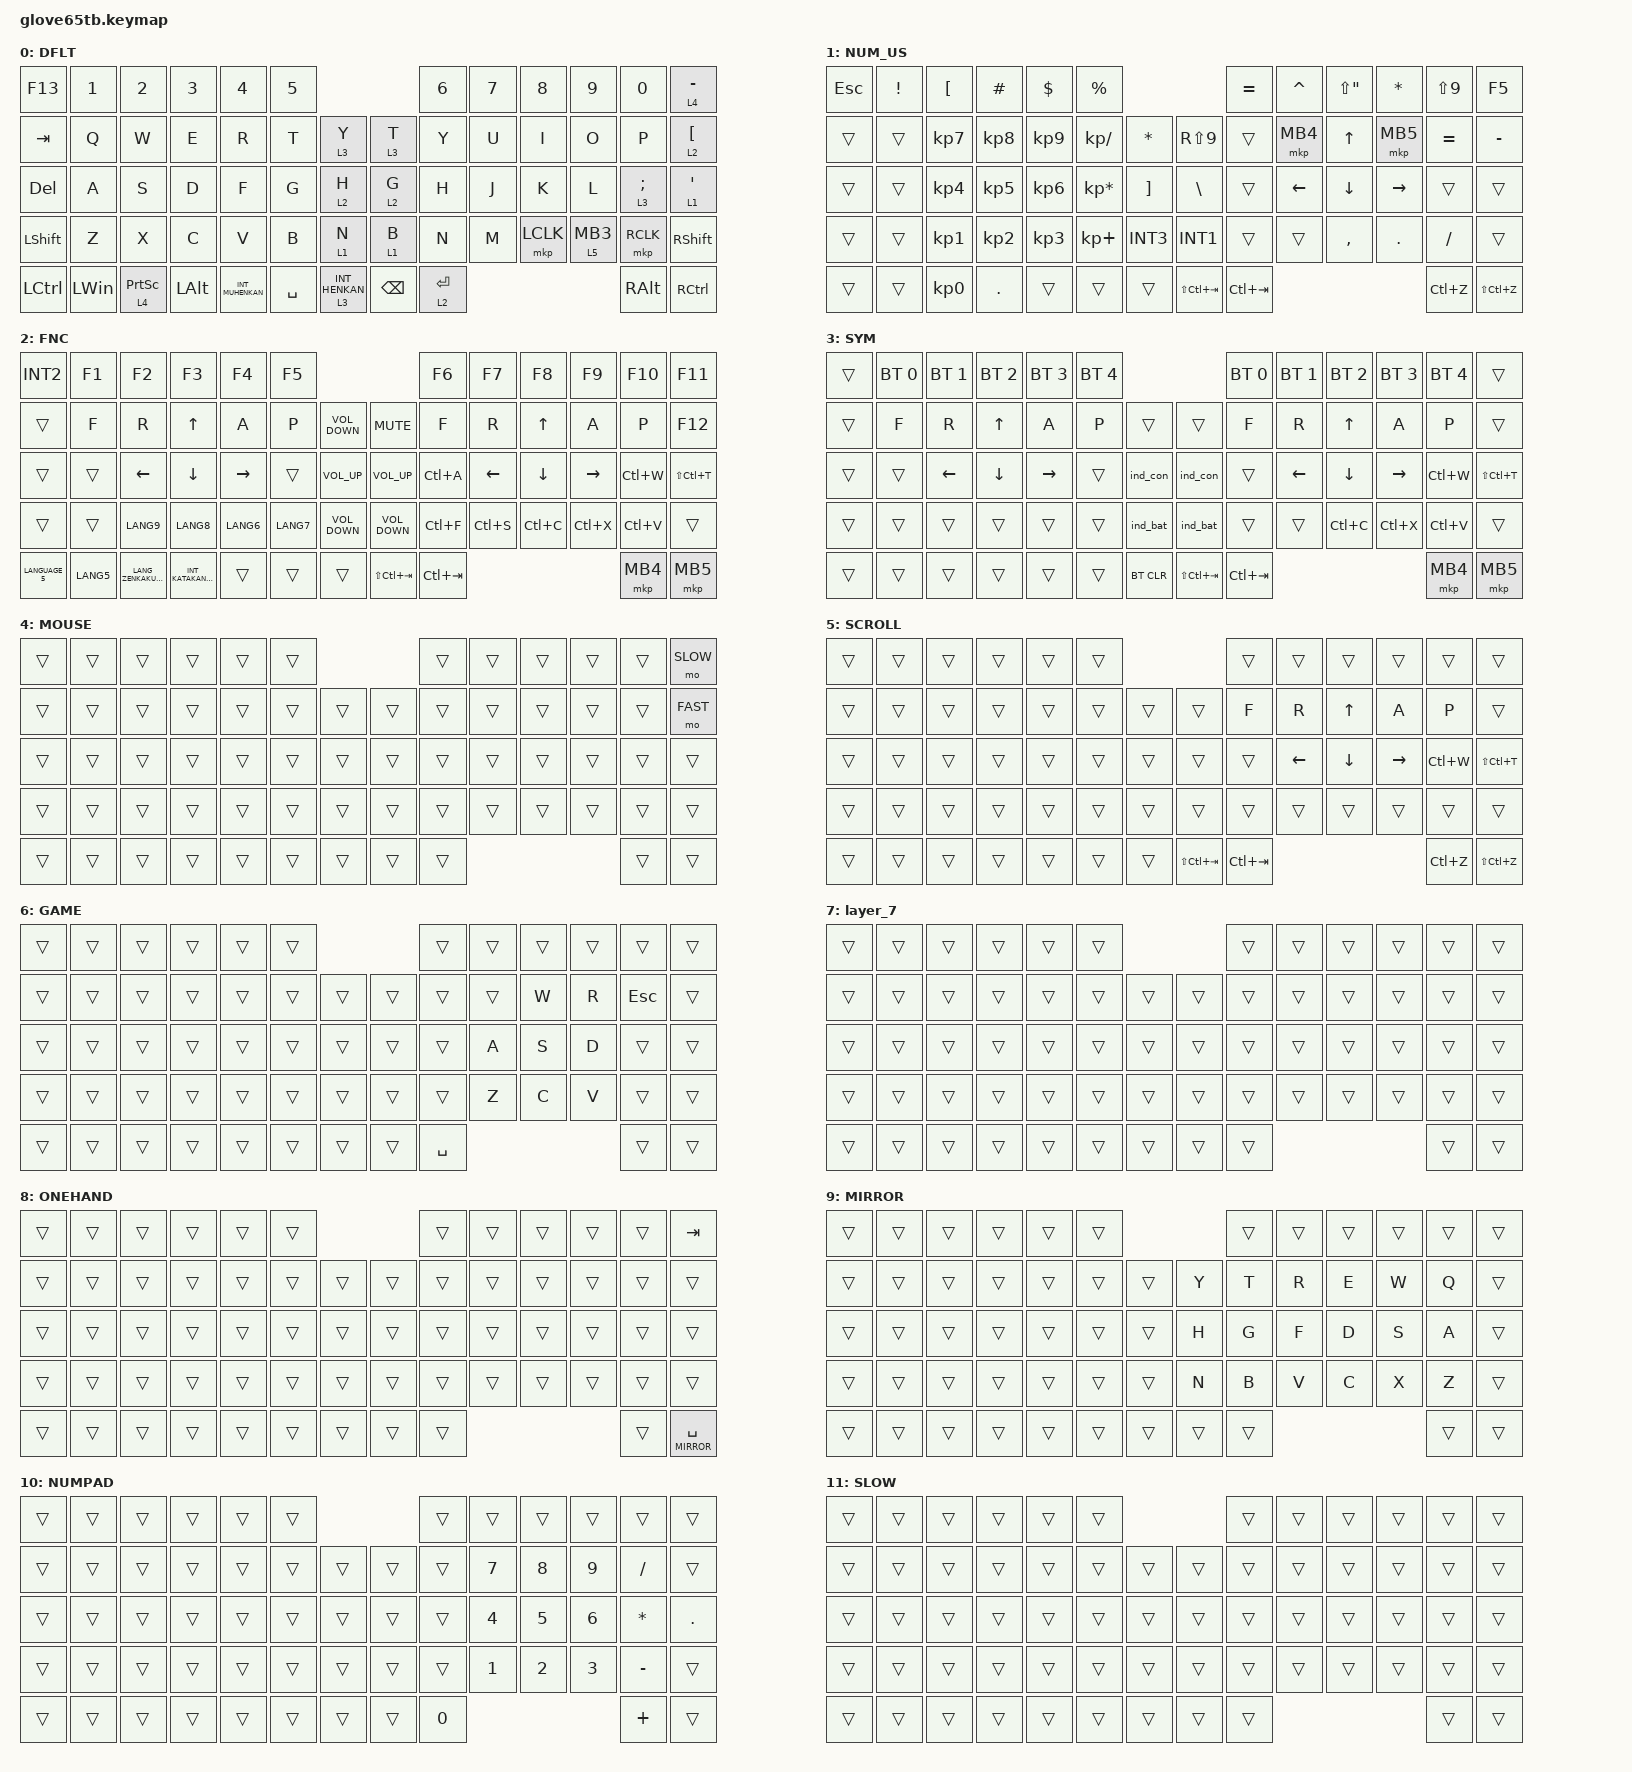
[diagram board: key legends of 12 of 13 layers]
#define ZMK_POINTING_DEFAULT_SCRL_VAL 150

#include <behaviors/rgbled_widget.dtsi>
#include <dt-bindings/zmk/input_transform.h>
#include <input/processors.dtsi>
#include <zephyr/dt-bindings/input/input-event-codes.h>
#include <behaviors.dtsi>
#include <dt-bindings/zmk/bt.h>
#include <dt-bindings/zmk/keys.h>
#include <dt-bindings/zmk/pointing.h>

// Layer Numbering

#define DEFAULT 0
#define NUM     1
#define SYM     2
#define FUN     3
#define MOUSE   4
#define SCROLL  5
#define GAME    6
#define ONEHAND 8
#define MIRROR  9
#define NUMPAD  10
#define SLOW    11
#define FAST    12

&mmv {
    delay-ms = <20>;
    trigger-period-ms = <5>;
    time-to-max-speed-ms = <100>;
    acceleration-exponent = <2>;
};

&msc {
    delay-ms = <3>;
    trigger-period-ms = <3>;
    time-to-max-speed-ms = <100>;
    acceleration-exponent = <0>;
};

/ {
    input_processors {
        zip_wheel_scaler: zip_wheel_scaler {
            compatible = "zmk,input-processor-scaler";
            #input-processor-cells = <2>;
            type = <INPUT_EV_REL>;
            codes = <INPUT_REL_WHEEL>;
            track-remainders;
        };
    };
};

/ {
    combos {
        compatible = "zmk,combos";

        scroll {
            bindings = <&mo 5>;
            key-positions = <50 51>;
        };

        toggle_onehand {
            bindings = <&tog ONEHAND>;
            key-positions = <63 64>;
        };

        toggle_numpad {
            bindings = <&tog NUMPAD>;
            key-positions = <61 62>;
        };

        toggle_game {
            bindings = <&tog GAME>;
            key-positions = <40 53>;
        };

        check_bt_connection {
            bindings = <&ind_con>;
            key-positions = <54 64>;
        };
    };

    behaviors {
        sensor_rotate_kp: sensor_rotate_kp {
            compatible = "zmk,behavior-sensor-rotate-var";
            #sensor-binding-cells = <2>;
            bindings = <&kp>, <&kp>;
        };

        mouse_wheel_scroll: mouse_wheel_scroll {
            compatible = "zmk,behavior-sensor-rotate-var";
            #sensor-binding-cells = <2>;
            bindings = <&msc>, <&msc>;

            tap-ms = <20>;
        };

        lt_mouse_layer: lt_mouse_layer {
            compatible = "zmk,behavior-hold-tap";
            label = "LAYER_TAP_MOUSE";
            bindings = <&mo>, <&mkp>;

            #binding-cells = <2>;
            tapping-term-ms = <200>;
        };
    };

    keymap {
        compatible = "zmk,keymap";

        default_layer {
            label = "DFLT";
            bindings = <
&kp F13         &kp N1        &kp N2             &kp N3        &kp N4              &kp N5                                        &kp N6       &kp N7  &kp N8     &kp N9                 &kp N0           &lt 4 MINUS
&kp TAB         &kp Q         &kp W              &kp E         &kp R               &kp T        &lt 3 Y           &lt 3 T        &kp Y        &kp U   &kp I      &kp O                  &kp P            &lt 2 LBKT
&kp DEL         &kp A         &kp S              &kp D         &kp F               &kp G        &lt 2 H           &lt 2 G        &kp H        &kp J   &kp K      &kp L                  &lt 3 SEMICOLON  &lt 1 APOS
&kp LEFT_SHIFT  &kp Z         &kp X              &kp C         &kp V               &kp B        &lt 1 N           &lt 1 B        &kp N        &kp M   &mkp LCLK  &lt_mouse_layer 5 MB3  &mkp RCLK        &kp RIGHT_SHIFT
&kp LCTRL       &kp LEFT_WIN  &lt 4 PRINTSCREEN  &kp LEFT_ALT  &kp INT_MUHENKAN    &kp SPACE    &lt 3 INT_HENKAN  &kp BACKSPACE  &lt 2 ENTER                                            &kp RIGHT_ALT    &kp RCTRL
            >;

            sensor-bindings = <&mouse_wheel_scroll SCRL_UP SCRL_DOWN>;
        };

        num_us_layer {
            label = "NUM_US";
            bindings = <
&kp ESC  &kp EXCL  &kp LBKT         &kp HASH         &kp DOLLAR       &kp PERCENT                                  &kp EQUAL    &kp CARET       &kp LS(DOUBLE_QUOTES)  &kp ASTRK        &kp LS(N9)  &kp F5
&trans   &trans    &kp KP_NUMBER_7  &kp KP_NUMBER_8  &kp KP_NUMBER_9  &kp KP_DIVIDE    &kp ASTRK  &kp RS(N9)       &trans       &mkp MB4        &kp UP_ARROW           &mkp MB5         &kp EQUAL   &kp MINUS
&trans   &trans    &kp KP_NUMBER_4  &kp KP_NUMBER_5  &kp KP_NUMBER_6  &kp KP_ASTERISK  &kp RBKT   &kp BSLH         &trans       &kp LEFT_ARROW  &kp DOWN_ARROW         &kp RIGHT_ARROW  &trans      &trans
&trans   &trans    &kp KP_NUMBER_1  &kp KP_NUMBER_2  &kp KP_NUMBER_3  &kp KP_PLUS      &kp INT3   &kp INT1         &trans       &trans          &kp COMMA              &kp PERIOD       &kp SLASH   &trans
&trans   &trans    &kp KP_NUMBER_0  &kp PERIOD       &trans           &trans           &trans     &kp LS(LC(TAB))  &kp LC(TAB)                                                          &kp LC(Z)   &kp LS(LC(Z))
            >;
        };

        function_layer {
            label = "FNC";
            bindings = <
&kp INT2        &kp F1     &kp F2                   &kp F3                    &kp F4           &kp F5                                           &kp F6       &kp F7          &kp F8          &kp F9           &kp F10    &kp F11
&trans          &kp F      &kp R                    &kp UP_ARROW              &kp A            &kp P      &kp C_VOLUME_DOWN  &kp K_MUTE         &kp F        &kp R           &kp UP_ARROW    &kp A            &kp P      &kp F12
&trans          &trans     &kp LEFT_ARROW           &kp DOWN_ARROW            &kp RIGHT_ARROW  &trans     &kp C_VOLUME_UP    &kp C_VOLUME_UP    &kp LC(A)    &kp LEFT_ARROW  &kp DOWN_ARROW  &kp RIGHT_ARROW  &kp LC(W)  &kp LS(LC(T))
&trans          &trans     &kp LANG9                &kp LANG8                 &kp LANG6        &kp LANG7  &kp C_VOLUME_DOWN  &kp C_VOLUME_DOWN  &kp LC(F)    &kp LC(S)       &kp LC(C)       &kp LC(X)        &kp LC(V)  &trans
&kp LANGUAGE_5  &kp LANG5  &kp LANG_ZENKAKUHANKAKU  &kp INT_KATAKANAHIRAGANA  &trans           &trans     &trans             &kp LS(LC(TAB))    &kp LC(TAB)                                                   &mkp MB4   &mkp MB5
            >;

            sensor-bindings = <&sensor_rotate_kp C_VOLUME_DOWN C_VOLUME_UP>;
        };

        symbol_layer {
            label = "SYM";
            bindings = <
&trans  &bt BT_SEL 0  &bt BT_SEL 1  &bt BT_SEL 2  &bt BT_SEL 3  &bt BT_SEL 4                             &bt BT_SEL 0 &bt BT_SEL 1    &bt BT_SEL 2    &bt BT_SEL 3     &bt BT_SEL 4 &trans
&trans  &kp F         &kp R         &kp UP        &kp A         &kp P         &trans    &trans           &kp F        &kp R           &kp UP_ARROW    &kp A            &kp P      &trans
&trans  &trans        &kp LEFT      &kp DOWN      &kp RIGHT     &trans        &ind_con  &ind_con         &trans       &kp LEFT_ARROW  &kp DOWN_ARROW  &kp RIGHT_ARROW  &kp LC(W)  &kp LS(LC(T))
&trans  &trans        &trans        &trans        &trans        &trans        &ind_bat  &ind_bat         &trans       &trans          &kp LC(C)       &kp LC(X)        &kp LC(V)  &trans
&trans  &trans        &trans        &trans        &trans        &trans        &bt BT_CLR  &kp LS(LC(TAB))  &kp LC(TAB)                                                   &mkp MB4   &mkp MB5
            >;
        };

        mouse_layer {
            label = "MOUSE";
            bindings = <
&trans  &trans  &trans  &trans  &trans  &trans                                  &trans  &trans  &trans  &trans  &trans  &mo SLOW
&trans  &trans  &trans  &trans  &trans  &trans  &trans  &trans                  &trans  &trans  &trans  &trans  &trans  &mo FAST
&trans  &trans  &trans  &trans  &trans  &trans  &trans  &trans                  &trans  &trans  &trans  &trans  &trans  &trans
&trans  &trans  &trans  &trans  &trans  &trans  &trans  &trans                  &trans  &trans  &trans  &trans  &trans  &trans
&trans  &trans  &trans  &trans  &trans  &trans  &trans  &trans  &trans                                  &trans  &trans
            >;
        };

        scroll_layer {
            label = "SCROLL";
            bindings = <
&trans  &trans  &trans  &trans  &trans  &trans                           &trans       &trans    &trans    &trans     &trans     &trans
&trans  &trans  &trans  &trans  &trans  &trans  &trans  &trans           &kp F        &kp R     &kp UP    &kp A      &kp P      &trans
&trans  &trans  &trans  &trans  &trans  &trans  &trans  &trans           &trans       &kp LEFT  &kp DOWN  &kp RIGHT  &kp LC(W)  &kp LS(LC(T))
&trans  &trans  &trans  &trans  &trans  &trans  &trans  &trans           &trans       &trans    &trans    &trans     &trans     &trans
&trans  &trans  &trans  &trans  &trans  &trans  &trans  &kp LS(LC(TAB))  &kp LC(TAB)                                 &kp LC(Z)  &kp LS(LC(Z))
            >;
        };

        game_layer {
            label = "GAME";
            bindings = <
&trans  &trans  &trans  &trans  &trans  &trans                                  &trans  &trans  &trans  &trans    &trans   &trans
&trans  &trans  &trans  &trans  &trans  &trans  &trans  &trans                  &trans  &trans  &kp W   &kp R     &kp ESC  &trans
&trans  &trans  &trans  &trans  &trans  &trans  &trans  &trans                  &trans  &kp A   &kp S   &kp D     &trans   &trans
&trans  &trans  &trans  &trans  &trans  &trans  &trans  &trans                  &trans  &kp Z   &kp C   &kp V     &trans   &trans
&trans  &trans  &trans  &trans  &trans  &trans  &trans  &trans  &kp SPACE                                &trans   &trans
            >;
        };

        layer_7 {
            bindings = <
&trans  &trans  &trans  &trans  &trans  &trans                  &trans  &trans  &trans  &trans  &trans  &trans
&trans  &trans  &trans  &trans  &trans  &trans  &trans  &trans  &trans  &trans  &trans  &trans  &trans  &trans
&trans  &trans  &trans  &trans  &trans  &trans  &trans  &trans  &trans  &trans  &trans  &trans  &trans  &trans
&trans  &trans  &trans  &trans  &trans  &trans  &trans  &trans  &trans  &trans  &trans  &trans  &trans  &trans
&trans  &trans  &trans  &trans  &trans  &trans  &trans  &trans  &trans                          &trans  &trans
            >;
        };

        onehand_layer {
            label = "ONEHAND";
            bindings = <
&trans  &trans  &trans  &trans  &trans  &trans                                    &trans  &trans  &trans  &trans  &trans          &kp TAB
&trans  &trans  &trans  &trans  &trans  &trans  &trans  &trans                    &trans  &trans  &trans  &trans  &trans          &trans
&trans  &trans  &trans  &trans  &trans  &trans  &trans  &trans                    &trans  &trans  &trans  &trans  &trans          &trans
&trans  &trans  &trans  &trans  &trans  &trans  &trans  &trans                    &trans  &trans  &trans  &trans  &trans          &trans
&trans  &trans  &trans  &trans  &trans  &trans  &trans  &trans  &trans                                            &trans          &lt MIRROR SPACE
            >;
        };

        mirror_layer {
            label = "MIRROR";
            bindings = <
&trans  &trans  &trans  &trans  &trans  &trans                  &trans  &trans  &trans  &trans  &trans  &trans
&trans  &trans  &trans  &trans  &trans  &trans  &trans  &kp Y   &kp T   &kp R   &kp E   &kp W   &kp Q   &trans
&trans  &trans  &trans  &trans  &trans  &trans  &trans  &kp H   &kp G   &kp F   &kp D   &kp S   &kp A   &trans
&trans  &trans  &trans  &trans  &trans  &trans  &trans  &kp N   &kp B   &kp V   &kp C   &kp X   &kp Z   &trans
&trans  &trans  &trans  &trans  &trans  &trans  &trans  &trans  &trans                          &trans  &trans
            >;
        };

        numpad_layer {
            label = "NUMPAD";
            bindings = <
&trans  &trans  &trans  &trans  &trans  &trans                                  &trans  &trans  &trans  &trans     &trans     &trans
&trans  &trans  &trans  &trans  &trans  &trans  &trans  &trans                  &trans  &kp N7  &kp N8  &kp N9     &kp FSLH   &trans
&trans  &trans  &trans  &trans  &trans  &trans  &trans  &trans                  &trans  &kp N4  &kp N5  &kp N6     &kp STAR   &kp DOT
&trans  &trans  &trans  &trans  &trans  &trans  &trans  &trans                  &trans  &kp N1  &kp N2  &kp N3     &kp MINUS  &trans
&trans  &trans  &trans  &trans  &trans  &trans  &trans  &trans  &kp N0                                  &kp PLUS   &trans
            >;
        };

        slow_layer {
            label = "SLOW";
            bindings = <
&trans  &trans  &trans  &trans  &trans  &trans                  &trans  &trans  &trans  &trans  &trans  &trans
&trans  &trans  &trans  &trans  &trans  &trans  &trans  &trans  &trans  &trans  &trans  &trans  &trans  &trans
&trans  &trans  &trans  &trans  &trans  &trans  &trans  &trans  &trans  &trans  &trans  &trans  &trans  &trans
&trans  &trans  &trans  &trans  &trans  &trans  &trans  &trans  &trans  &trans  &trans  &trans  &trans  &trans
&trans  &trans  &trans  &trans  &trans  &trans  &trans  &trans  &trans                          &trans  &trans
            >;
        };

        fast_layer {
            label = "FAST";
            bindings = <
&trans  &trans  &trans  &trans  &trans  &trans                  &trans  &trans  &trans  &trans  &trans  &trans
&trans  &trans  &trans  &trans  &trans  &trans  &trans  &trans  &trans  &trans  &trans  &trans  &trans  &trans
&trans  &trans  &trans  &trans  &trans  &trans  &trans  &trans  &trans  &trans  &trans  &trans  &trans  &trans
&trans  &trans  &trans  &trans  &trans  &trans  &trans  &trans  &trans  &trans  &trans  &trans  &trans  &trans
&trans  &trans  &trans  &trans  &trans  &trans  &trans  &trans  &trans                          &trans  &trans
            >;
        };
    };

    conditional_layers {
        compatible = "zmk,conditional-layers";

        Test {
            if-layers = <1 3>;
            then-layer = <7>;
        };
    };
};
